# Cortex-M4_RTSM register map
Vendor: ARM Ltd.
CPU: Cortex-M4_RTSM r0p0, little endian, MPU, FPU, VTOR, vendor SysTick, 8 interrupt priority bits
Registers are 32-bit, read-write, no defined reset value unless marked. A register's access mark holds for its fields unless they carry their own. Offsets are from the block's base; [hi:lo] are bit positions; {n}, {i} and the like mark numbered series; 'fields as' and 'values as' point back to an identical list.

## FPE — System Control registers for the FP extension
Base ?
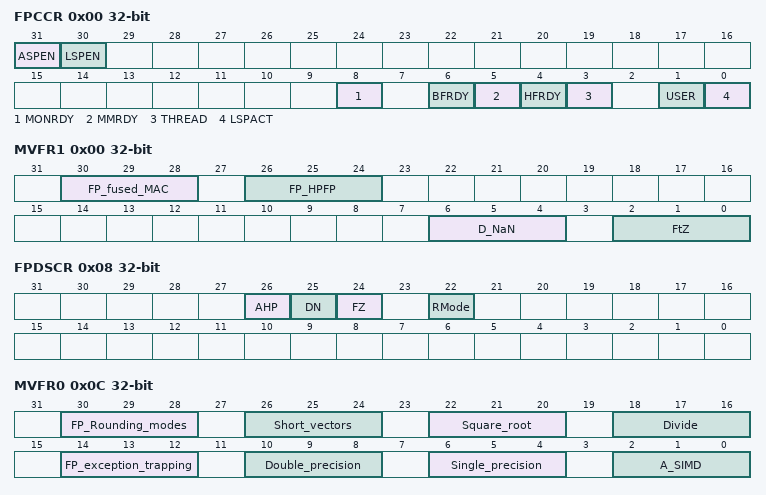
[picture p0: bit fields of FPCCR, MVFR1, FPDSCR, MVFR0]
0x00 FPCCR
  [31] ASPEN — When this bit is set to 1, execution of a floating-point instruction sets the CONTROL.FPCA bit to 1
  [30] LSPEN — Enables lazy context save of FP state
  [8] MONRDY — Indicates whether the software executing when the processor allocated the FP stack frame was able to set the DebugMonitor exception to pending
  [6] BFRDY — Indicates whether the software executing when the processor allocated the FP stack frame was able to set the BusFault exception to pending
  [5] MMRDY — Indicates whether the software executing when the processor allocated the FP stack frame was able to set the MemManage exception to pending
  [4] HFRDY — Indicates whether the software executing when the processor allocated the FP stack frame was able to set the HardFault exception to pending
  [3] THREAD — Indicates the processor mode when it allocated the FP stack frame
  [1] USER — Indicates the privilege level of the software executing when the processor allocated the FP stack frame
  [0] LSPACT — Indicates whether Lazy preservation of the FP state is active
0x00 MVFR1 ro
  [30:28] FP_fused_MAC — Indicates whether the FP supports fused multiply accumulate operations
  [26:24] FP_HPFP — Indicates whether the FP supports half-precision floating-point conversion operations
  [6:4] D_NaN — Indicates whether the FP hardware implementation supports only the Default NaN mode
  [2:0] FtZ — Indicates whether the FP hardware implementation supports only the Flush-to-Zero mode of operation
0x04 FPCAR
0x08 FPDSCR
  [26] AHP — Default value for FPSCR.AHP
  [25] DN — Default value for FPSCR.DN
  [24] FZ — Default value for FPSCR.FZ
  [22] RMode — Default value for FPSCR.RMode
0x0C MVFR0 ro
  [30:28] FP_Rounding_modes — Indicates the rounding modes supported by the FP floating-point hardware
  [26:24] Short_vectors — Indicates the hardware support for FP short vectors
  [22:20] Square_root — Indicates the hardware support for FP square root operations
  [18:16] Divide — Indicates the hardware support for FP divide operations
  [14:12] FP_exception_trapping — Indicates whether the FP hardware implementation supports exception trapping
  [10:8] Double_precision — Indicates the hardware support for FP double-precision operations
  [6:4] Single_precision — Indicates the hardware support for FP single-precision operations
  [2:0] A_SIMD — Indicates the size of the FP register bank

## SysTick — System Timer registers
Base ?
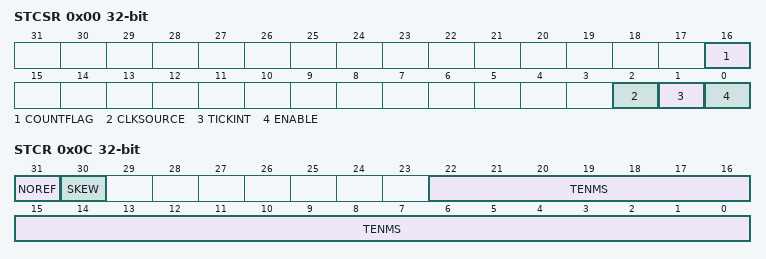
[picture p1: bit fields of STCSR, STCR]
0x00 STCSR
  [16] COUNTFLAG — Indicates whether the counter has counted to 0 since the last read of this register
  [2] CLKSOURCE — Indicates the SysTick clock source
  [1] TICKINT — Indicates whether counting to 0 causes the status of the SysTick exception to change to pending
  [0] ENABLE — Indicates the enabled status of the SysTick counter
0x04 STRVR
  [22:0] RELOAD — The value to load into the SYST_CVR register when the counter reaches 0
0x08 STCVR
  [22:0] CURRENT — This is the value of the counter at the time it is sampled
0x0C STCR ro
  [31] NOREF — Indicates whether the IMPLEMENTATION DEFINED reference clock is provided
  [30] SKEW — Indicates whether the 10ms calibration value is exact
  [22:0] TENMS — Optionally, holds a reload value to be used for 10ms (100Hz) timing, subject to system clock skew errors

## MPU — Memory Protection Unit
Base ?
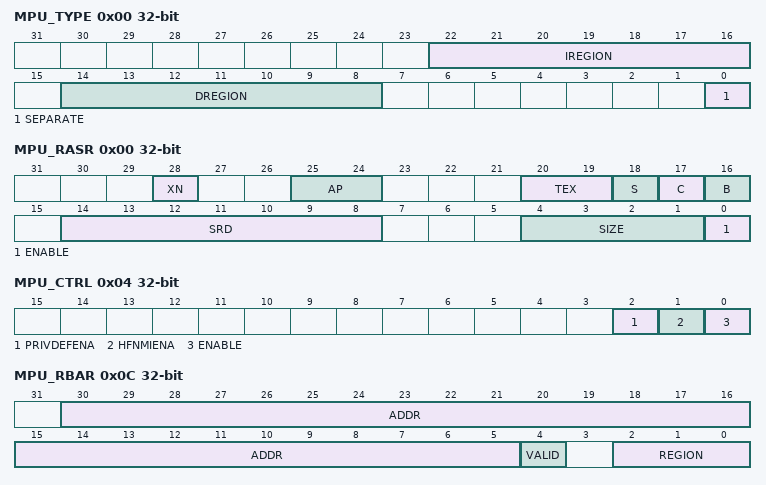
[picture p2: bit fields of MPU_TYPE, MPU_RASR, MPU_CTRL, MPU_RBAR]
0x00 MPU_TYPE ro
  [22:16] IREGION — Number of instruction regions supported by the MPU
  [14:8] DREGION — Number of regions supported by the MPU
  [0] SEPARATE — Indicates support for separate instruction and data address maps
0x00 MPU_RASR
  [28] XN — Execute Never
  [25:24] AP — Access permissions
  [20:19] TEX — MPU Region Attribute field
  [18] S — MPU Region Attribute field: Sharable
  [17] C — MPU Region Attribute field
  [16] B — MPU Region Attribute field
  [14:8] SRD — Subregion Disable
  [4:1] SIZE — Indicates the region size
  [0] ENABLE — Enables this region
0x04 MPU_CTRL
  [2] PRIVDEFENA — When the ENABLE bit is set to 1, Enables the default memory map as a background region for privileged access
  [1] HFNMIENA — When the ENABLE bit is set to 1, controls whether handlers executing with priority less than 0 access memory with the MPU enabled or with the MPU disabled
  [0] ENABLE — Enables the MPU
0x08 MPU_RNR
  [6:0] REGION — Indicates the memory region accessed by MPU_RBAR and MPU_RSAR
0x0C MPU_RBAR
  [30:5] ADDR — Base address of the region
  [4] VALID — On writes, indicates whether the region to update is specified by MPU_RNR.REGION, or by the REGION value specified in this write. When using the REGION value specified by this write, MPU_RNR.REGION is updated to this value
  [2:0] REGION — On writes, can specify the number of the region to update. On reads, returns bits [3:0] of MPU_RNR
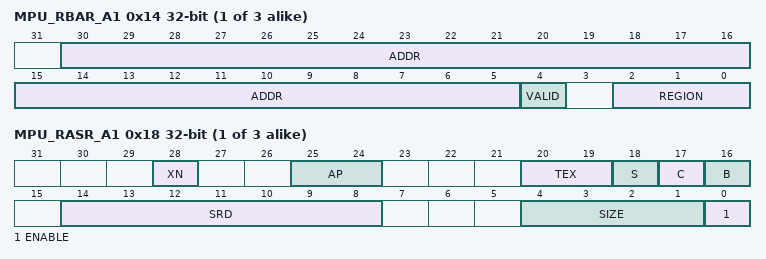
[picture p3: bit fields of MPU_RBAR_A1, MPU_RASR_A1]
{0xC+8i} MPU_RBAR_A{i} (i=1..3)
  fields as MPU_RBAR
{0x10+8i} MPU_RASR_A{i} (i=1..3)
  fields as MPU_RASR
